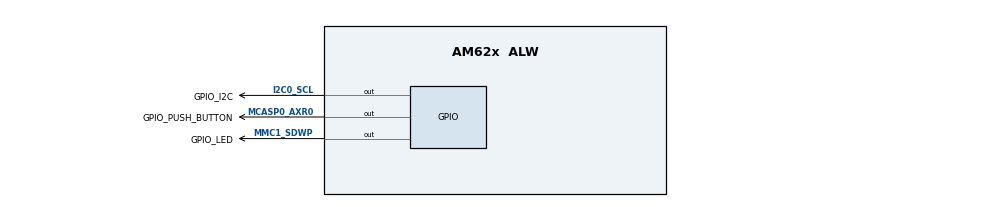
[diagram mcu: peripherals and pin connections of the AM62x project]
/**
 * @cliArgs --device "AM62x" --part "Default" --package "ALW" --context "r5fss0-0" --product "MCU_PLUS_SDK@07.03.01"
 * @versions {"tool":"1.26.2+4477"}
 */

/**
 * Import the modules used in this configuration.
 */
const gpio        = scripting.addModule("/drivers/gpio/gpio", {}, false);
const gpio1       = gpio.addInstance();
const gpio2       = gpio.addInstance();
const gpio3       = gpio.addInstance();
const gpio4       = gpio.addInstance();
const gpio5       = gpio.addInstance();
const gpio6       = gpio.addInstance();
const gpio7       = gpio.addInstance();
const gpio8       = gpio.addInstance();
const gpio9       = gpio.addInstance();
const gpio10      = gpio.addInstance();
const clock       = scripting.addModule("/kernel/dpl/clock");
const debug_log   = scripting.addModule("/kernel/dpl/debug_log");
const mpu_armv7   = scripting.addModule("/kernel/dpl/mpu_armv7", {}, false);
const mpu_armv71  = mpu_armv7.addInstance();
const mpu_armv72  = mpu_armv7.addInstance();
const mpu_armv73  = mpu_armv7.addInstance();
const mpu_armv74  = mpu_armv7.addInstance();
const mpu_armv75  = mpu_armv7.addInstance();
const mpu_armv76  = mpu_armv7.addInstance();
const mpu_armv77  = mpu_armv7.addInstance();
const mpu_armv78  = mpu_armv7.addInstance();
const mpu_armv79  = mpu_armv7.addInstance();
const mpu_armv710 = mpu_armv7.addInstance();

/**
 * Write custom configuration values to the imported modules.
 */
gpio1.$name                = "GPIO_LED";
gpio1.pinDir               = "OUTPUT";
gpio1.GPIO.$assign         = "GPIO1";
gpio1.GPIO.gpioPin.$assign = "MMC1_SDWP";

gpio2.$name                = "GPIO_PUSH_BUTTON";
gpio2.trigType             = "RISE_EDGE";
gpio2.GPIO.$assign         = "GPIO1";
gpio2.GPIO.gpioPin.$assign = "MCASP0_AXR0";

gpio3.$name                = "GPIO_I2C";
gpio3.pinDir               = "OUTPUT";
gpio3.trigType             = "FALL_EDGE";
gpio3.GPIO.$assign         = "GPIO1";
gpio3.GPIO.gpioPin.$assign = "I2C0_SCL";

gpio4.$name        = "GPIO_MCAN";
gpio4.pinDir       = "OUTPUT";
gpio4.trigType     = "BOTH_EDGE";
gpio4.GPIO.$assign = "GPIO1";

gpio5.$name    = "GPIO_OSPI_D1";
gpio5.pinDir   = "OUTPUT";
gpio5.trigType = "RISE_EDGE";

gpio6.$name        = "GPIO_OSPI_D2";
gpio6.pinDir       = "OUTPUT";
gpio6.trigType     = "FALL_EDGE";
gpio6.GPIO.$assign = "GPIO1";

gpio7.$name        = "GPIO_INPUT";
gpio7.trigType     = "RISE_EDGE";
gpio7.GPIO.$assign = "GPIO1";

gpio8.$name        = "GPIO_OUTPUT";
gpio8.pinDir       = "OUTPUT";
gpio8.trigType     = "RISE_EDGE";
gpio8.GPIO.$assign = "GPIO1";

gpio9.$name        = "CONFIG_GPIO0";
gpio9.GPIO.$assign = "GPIO0";

gpio10.$name = "CONFIG_GPIO1";

debug_log.enableUartLog = true;
debug_log.enableCssLog  = false;
debug_log.uartTrace     = true;
debug_log.uartLog.$name = "CONFIG_UART0";

mpu_armv71.size         = 31;
mpu_armv71.attributes   = "Device";
mpu_armv71.allowExecute = false;
mpu_armv71.$name        = "REGISTER_REGION";

mpu_armv72.accessPermissions = "Supervisor RD+WR, User RD";
mpu_armv72.size              = 7;
mpu_armv72.$name             = "TCMA_VEC";

mpu_armv73.$name             = "CONFIG_MPU_REGION2";
mpu_armv73.accessPermissions = "Supervisor RD+WR, User RD";
mpu_armv73.baseAddr          = 0x41C00000;
mpu_armv73.size              = 19;

mpu_armv74.$name             = "CONFIG_MPU_REGION3";
mpu_armv74.accessPermissions = "Supervisor RD+WR, User RD";
mpu_armv74.baseAddr          = 0x70000000;
mpu_armv74.size              = 16;

mpu_armv75.baseAddr = 0x80000000;
mpu_armv75.size     = 31;
mpu_armv75.$name    = "CONFIG_MPU_DDR";

mpu_armv76.baseAddr   = 0x41010000;
mpu_armv76.size       = 15;
mpu_armv76.attributes = "NonCached";
mpu_armv76.$name      = "TCMB";

mpu_armv77.size       = 15;
mpu_armv77.attributes = "NonCached";
mpu_armv77.$name      = "TCMA";

mpu_armv78.baseAddr = 0x79100000;
mpu_armv78.size     = 19;
mpu_armv78.$name    = "CONFIG_MPU_MCU_MSRAM";

mpu_armv79.baseAddr = 0x60000000;
mpu_armv79.size     = 26;
mpu_armv79.$name    = "CONFIG_MPU_FLASH";

mpu_armv710.baseAddr = 0x43C00000;
mpu_armv710.size     = 18;
mpu_armv710.$name    = "HSM_RAM";

/**
 * Pinmux solution for unlocked pins/peripherals. This ensures that minor changes to the automatic solver in a future
 * version of the tool will not impact the pinmux you originally saw.  These lines can be completely deleted in order to
 * re-solve from scratch.
 */
gpio4.GPIO.gpioPin.$suggestSolution              = "RGMII2_RD0";
gpio5.GPIO.$suggestSolution                      = "GPIO0";
gpio5.GPIO.gpioPin.$suggestSolution              = "OSPI0_DQS";
gpio6.GPIO.gpioPin.$suggestSolution              = "RGMII2_RXC";
gpio7.GPIO.gpioPin.$suggestSolution              = "RGMII2_RX_CTL";
gpio8.GPIO.gpioPin.$suggestSolution              = "RGMII2_TD3";
gpio9.GPIO.gpioPin.$suggestSolution              = "OSPI0_LBCLKO";
gpio10.GPIO.$suggestSolution                     = "GPIO0";
gpio10.GPIO.gpioPin.$suggestSolution             = "OSPI0_CLK";
debug_log.uartLog.WKUP_UART.$suggestSolution     = "WKUP_USART0";
debug_log.uartLog.WKUP_UART.RXD.$suggestSolution = "WKUP_UART0_RXD";
debug_log.uartLog.WKUP_UART.TXD.$suggestSolution = "WKUP_UART0_TXD";
